# R7FA0L107 register map
Vendor: Renesas Electronics Corporation; Series: RA0; File version: 1.10.01
CPU: CM23 r1p0, little endian, no MPU, no FPU, VTOR, 2 interrupt priority bits, 64 interrupts
Registers are 16-bit, read-write, reset 0x0 unless marked. A register's access mark holds for its fields unless they carry their own. Offsets are from the block's base; [hi:lo] are bit positions; {n}, {i} and the like mark numbered series.

## PORGA — Product Organize
Base 0x400A1000
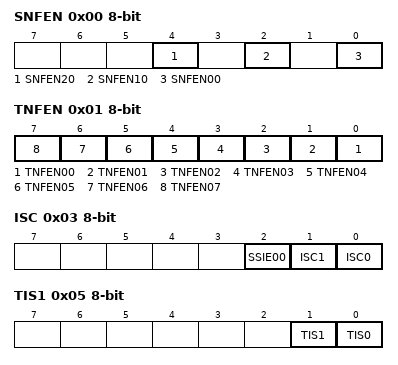
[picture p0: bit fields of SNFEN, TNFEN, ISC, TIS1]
0x00 SNFEN 8-bit — SAU Noise Filter Enable Register
  [all] fields
    0=Noise filter OFF; 1=Noise filter ON
  [4] SNFEN20 — Use of Noise Filter of RXD2 Pin
  [2] SNFEN10 — Use of Noise Filter of RXD1 Pin
  [0] SNFEN00 — Use of Noise Filter of RXD0 Pin
0x01 TNFEN 8-bit — TAU Noise Filter Enable Register
  [all] fields
    0=Turns the noise filter off; 1=Turns the noise filter on
  [n] TNFEN{n:02} (n=0..7) — Enabling or Disabling Use of the Noise Filter for the TI{n:02} Pin
0x03 ISC 8-bit — Input Switch Control Register
  [2] SSIE00 — Setting of the SSI00 Input of Channel 0 in the Communications Through SPI00 in the Slave Mode
    0=The SSI00 input is disabled; 1=The SSI00 input is enabled
  [1] ISC1 — Switching Channel 7 Input of Timer Array Unit
    0=Uses the input signal of the TI07 pin as a timer input (normal operation); 1=Input signal of the RXD2 pin is used as timer input (detects the wakeup signal and measures the low width of the break field and the pulse width of the sync field)
  [0] ISC0 — Switching External Interrupt (IRQ0) Input
    0=Uses the input signal of the IRQ0 pin as an external interrupt (normal operation); 1=Uses the input signal of the RXD2 pin as an external interrupt (wakeup signal detection)
0x04 TIS0 8-bit — Timer Input Select Register 0
  [2:0] TIS — Selection of Timer Input Used with Channel 5
    0=Input signal of timer input pin (TI05); 3=Middle-speed on-chip oscillator (MOCO); 4=Low-speed on-chip oscillator (LOCO); 5=Sub System clock (FSUB); other=Others (Setting prohibited)
0x05 TIS1 8-bit — Timer Input Select Register 1
  [1] TIS1 — Selection of Timer Input Used with Channel 1
    0=Input signal of timer input pin (TI01); 1=Event input signal from ELC
  [0] TIS0 — Selection of Timer Input Used with Channel 0
    0=Input signal of timer input pin (TI00); 1=Event input signal from ELC
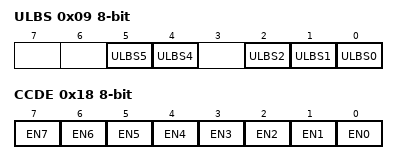
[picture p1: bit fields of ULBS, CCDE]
0x09 ULBS 8-bit — UART Loopback Select Register
  [5] ULBS5 — Selection of the UARTA1 Loopback Function
    0=Inputs the states of the RXDA1 pin of serial array unit UARTA1 to the reception shift register; 1=Loops back output from the transmission shift register to the reception shift register
  [4] ULBS4 — Selection of the UARTA0 Loopback Function
    0=Inputs the states of the RXDA0 pin of serial array unit UARTA0 to the reception shift register; 1=Loops back output from the transmission shift register to the reception shift register
  [2] ULBS2 — Selection of the UART2 Loopback Function
    0=Inputs the states of the RXD2 pin of serial array unit UART2 to the reception shift register; 1=Loops back output from the transmission shift register to the reception shift register
  [1] ULBS1 — Selection of the UART1 Loopback Function
    0=Inputs the states of the RXD1 pin of serial array unit UART1 to the reception shift register; 1=Loops back output from the transmission shift register to the reception shift register
  [0] ULBS0 — Selection of the UART0 Loopback Function
    0=Inputs the states of the RXD0 pin of serial array unit UART0 to the reception shift register; 1=Loops back output from the transmission shift register to the reception shift register
{0x10+i} CCS{i} (i=0..7) 8-bit — Output Current Select Register {i}
  [2:0] SET — Setting for the low-level output current
    0=Hi-Z; 1=2 mA; 2=5 mA; 3=10 mA; 4=15 mA (settings other than CCS4 to CCS7 are prohibited); other=Others (Setting prohibited)
0x18 CCDE 8-bit — Output Current Control Enable Register
  [all] fields
    0=Digital I/O (alternate function other than current control function); 1=Current control function
  [7] EN7 — Output Current Control Function Enable for CCD7 Pin
  [6] EN6 — Output Current Control Function Enable for CCD6 Pin
  [5] EN5 — Output Current Control Function Enable for CCD5 Pin
  [4] EN4 — Output Current Control Function Enable for CC0D4 Pin
  [n] EN{n} (n=0..3) — Output Current Control Function Enable for CCD{n} Pin
